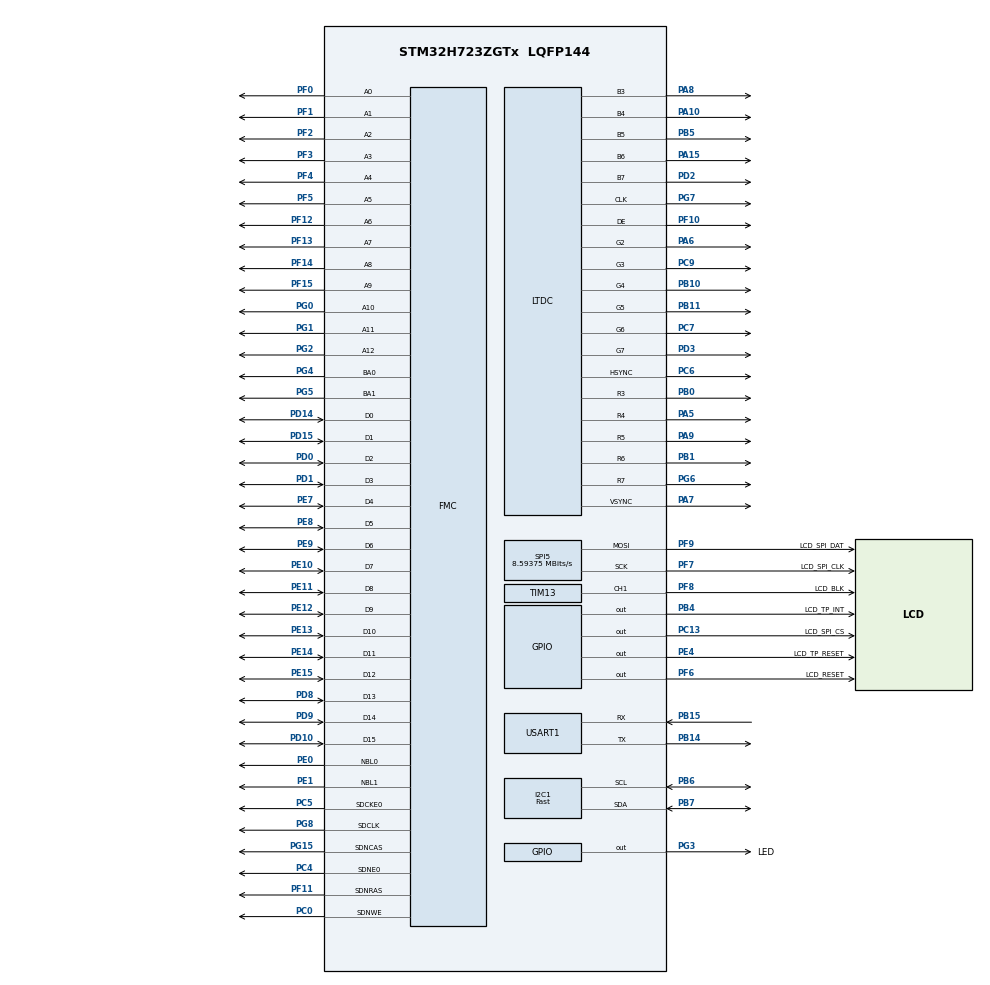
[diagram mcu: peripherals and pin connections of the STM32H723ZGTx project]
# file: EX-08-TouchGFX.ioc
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FMC.CASLatency1=FMC_SDRAM_CAS_LATENCY_2
FMC.ColumnBitsNumber1=FMC_SDRAM_COLUMN_BITS_NUM_9
FMC.ExitSelfRefreshDelay1=7
FMC.LoadToActiveDelay1=2
FMC.RCDDelay1=2
FMC.RPDelay1=2
FMC.ReadBurst1=FMC_SDRAM_RBURST_ENABLE
FMC.RowCycleDelay1=6
FMC.SDClockPeriod1=FMC_SDRAM_CLOCK_PERIOD_3
FMC.SelfRefreshTime1=4
FMC.WriteRecoveryTime1=2
I2C1.I2C_Speed_Mode=I2C_Fast
I2C1.Timing=0x00D049FB
LTDC.ActiveW=480
LTDC.Alpha_L0=255
LTDC.FBStartAdress_L0=0xC0000000
LTDC.HBP=50
LTDC.HFP=10
LTDC.ImageHeight_L0=480
LTDC.ImageWidth_L0=480
LTDC.Layers=0
LTDC.PixelFormat_L0=LTDC_PIXEL_FORMAT_RGB565
LTDC.VBP=20
LTDC.VFP=10
LTDC.VSync=8
LTDC.WindowX1_L0=480
LTDC.WindowY1_L0=480
Mcu.Family=STM32H7
Mcu.Name=STM32H723ZGTx
Mcu.Package=LQFP144
NVIC.LTDC_ER_IRQn=true\:5\:0\:true\:false\:true\:true\:true\:true
NVIC.LTDC_IRQn=true\:5\:0\:true\:false\:true\:true\:true\:true
NVIC.PriorityGroup=NVIC_PRIORITYGROUP_4
PA10.GPIO_Speed=GPIO_SPEED_FREQ_HIGH
PA10.Mode=RGB565
PA10.Signal=LTDC_B4
PA13(JTMS/SWDIO).Mode=Serial_Wire
PA13(JTMS/SWDIO).Signal=DEBUG_JTMS-SWDIO
PA14(JTCK/SWCLK).Mode=Serial_Wire
PA14(JTCK/SWCLK).Signal=DEBUG_JTCK-SWCLK
PA15(JTDI).GPIO_Speed=GPIO_SPEED_FREQ_HIGH
PA15(JTDI).Mode=RGB565
PA15(JTDI).Signal=LTDC_B6
PA5.GPIO_Speed=GPIO_SPEED_FREQ_HIGH
PA5.Mode=RGB565
PA5.Signal=LTDC_R4
PA6.GPIO_Speed=GPIO_SPEED_FREQ_HIGH
PA6.Mode=RGB565
PA6.Signal=LTDC_G2
PA7.GPIO_Speed=GPIO_SPEED_FREQ_HIGH
PA7.Mode=RGB565
PA7.Signal=LTDC_VSYNC
PA8.GPIO_Speed=GPIO_SPEED_FREQ_HIGH
PA8.Mode=RGB565
PA8.Signal=LTDC_B3
PA9.GPIO_Speed=GPIO_SPEED_FREQ_HIGH
PA9.Mode=RGB565
PA9.Signal=LTDC_R5
PB0.GPIO_Speed=GPIO_SPEED_FREQ_HIGH
PB0.Mode=RGB565
PB0.Signal=LTDC_R3
PB1.GPIO_Speed=GPIO_SPEED_FREQ_HIGH
PB1.Mode=RGB565
PB1.Signal=LTDC_R6
PB10.GPIO_Speed=GPIO_SPEED_FREQ_HIGH
PB10.Mode=RGB565
PB10.Signal=LTDC_G4
PB11.GPIO_Speed=GPIO_SPEED_FREQ_HIGH
PB11.Mode=RGB565
PB11.Signal=LTDC_G5
PB14.Mode=Asynchronous
PB14.Signal=USART1_TX
PB15.Mode=Asynchronous
PB15.Signal=USART1_RX
PB4(NJTRST).GPIO_Label=LCD_TP_INT
PB4(NJTRST).Signal=GPIO_Output
PB5.GPIO_Speed=GPIO_SPEED_FREQ_HIGH
PB5.Mode=RGB565
PB5.Signal=LTDC_B5
PB6.Mode=I2C
PB6.Signal=I2C1_SCL
PB7.Mode=I2C
PB7.Signal=I2C1_SDA
PC0.Signal=FMC_SDNWE
PC13.GPIO_Label=LCD_SPI_CS
PC13.PinState=GPIO_PIN_SET
PC13.Signal=GPIO_Output
PC4.Mode=SdramChipSelect1_1
PC4.Signal=FMC_SDNE0
PC5.Mode=SdramChipSelect1_1
PC5.Signal=FMC_SDCKE0
PC6.GPIO_Speed=GPIO_SPEED_FREQ_HIGH
PC6.Mode=RGB565
PC6.Signal=LTDC_HSYNC
PC7.GPIO_Speed=GPIO_SPEED_FREQ_HIGH
PC7.Mode=RGB565
PC7.Signal=LTDC_G6
PC9.GPIO_Speed=GPIO_SPEED_FREQ_HIGH
PC9.Mode=RGB565
PC9.Signal=LTDC_G3
PD0.Signal=FMC_D2_DA2
PD1.Signal=FMC_D3_DA3
PD10.Signal=FMC_D15_DA15
PD14.Signal=FMC_D0_DA0
PD15.Signal=FMC_D1_DA1
PD2.GPIO_Speed=GPIO_SPEED_FREQ_HIGH
PD2.Mode=RGB565
PD2.Signal=LTDC_B7
PD3.GPIO_Speed=GPIO_SPEED_FREQ_HIGH
PD3.Mode=RGB565
PD3.Signal=LTDC_G7
PD8.Signal=FMC_D13_DA13
PD9.Signal=FMC_D14_DA14
PE0.Signal=FMC_NBL0
PE1.Signal=FMC_NBL1
PE10.Signal=FMC_D7_DA7
PE11.Signal=FMC_D8_DA8
PE12.Signal=FMC_D9_DA9
PE13.Signal=FMC_D10_DA10
PE14.Signal=FMC_D11_DA11
PE15.Signal=FMC_D12_DA12
PE4.GPIO_Label=LCD_TP_RESET
PE4.Signal=GPIO_Output
PE7.Signal=FMC_D4_DA4
PE8.Signal=FMC_D5_DA5
PE9.Signal=FMC_D6_DA6
PF0.Signal=FMC_A0
PF1.Signal=FMC_A1
PF10.GPIO_Speed=GPIO_SPEED_FREQ_HIGH
PF10.Mode=RGB565
PF10.Signal=LTDC_DE
PF11.Signal=FMC_SDNRAS
PF12.Signal=FMC_A6
PF13.Signal=FMC_A7
PF14.Signal=FMC_A8
PF15.Signal=FMC_A9
PF2.Signal=FMC_A2
PF3.Signal=FMC_A3
PF4.Signal=FMC_A4
PF5.Signal=FMC_A5
PF6.GPIO_Label=LCD_RESET
PF6.PinState=GPIO_PIN_SET
PF6.Signal=GPIO_Output
PF7.GPIO_Label=LCD_SPI_CLK
PF7.GPIO_Speed=GPIO_SPEED_FREQ_HIGH
PF7.Mode=TX_Only_Simplex_Unidirect_Master
PF7.Signal=SPI5_SCK
PF8.GPIO_Label=LCD_BLK
PF8.Signal=S_TIM13_CH1
PF9.GPIO_Label=LCD_SPI_DAT
PF9.GPIO_Speed=GPIO_SPEED_FREQ_HIGH
PF9.Mode=TX_Only_Simplex_Unidirect_Master
PF9.Signal=SPI5_MOSI
PG0.Signal=FMC_A10
PG1.Signal=FMC_A11
PG15.Signal=FMC_SDNCAS
PG2.Signal=FMC_A12
PG3.GPIO_Label=LED
PG3.PinState=GPIO_PIN_SET
PG3.Signal=GPIO_Output
PG4.Signal=FMC_A14_BA0
PG5.Signal=FMC_A15_BA1
PG6.GPIO_Speed=GPIO_SPEED_FREQ_HIGH
PG6.Mode=RGB565
PG6.Signal=LTDC_R7
PG7.GPIO_Speed=GPIO_SPEED_FREQ_HIGH
PG7.Mode=RGB565
PG7.Signal=LTDC_CLK
PG8.Signal=FMC_SDCLK
PH0-OSC_IN.Mode=HSE-External-Oscillator
PH0-OSC_IN.Signal=RCC_OSC_IN
PH1-OSC_OUT.Mode=HSE-External-Oscillator
PH1-OSC_OUT.Signal=RCC_OSC_OUT
ProjectManager.HeapSize=0x200
ProjectManager.StackSize=0x400
ProjectManager.TargetToolchain=STM32CubeIDE
RCC.ADCFreq_Value=50390625
RCC.APB1Freq_Value=137500000
RCC.APB2Freq_Value=137500000
RCC.APB3Freq_Value=137500000
RCC.APB4Freq_Value=137500000
RCC.CortexFreq_Value=550000000
RCC.D1PPRE=RCC_APB3_DIV2
RCC.D2PPRE1=RCC_APB1_DIV2
RCC.D2PPRE2=RCC_APB2_DIV2
RCC.D3PPRE=RCC_APB4_DIV2
RCC.DIVM1=2
RCC.DIVN1=44
RCC.DIVP1=1
RCC.DIVR3=6
RCC.HCLKFreq_Value=275000000
RCC.HPRE=RCC_HCLK_DIV2
RCC.PLLFRACN=0
RCC.PLLSourceVirtual=RCC_PLLSOURCE_HSE
RCC.SYSCLKFreq_VALUE=550000000
RCC.SYSCLKSource=RCC_SYSCLKSOURCE_PLLCLK
RCC.USBFreq_Value=275000000
SH.FMC_A0.0=FMC_A0,13b-sda1
SH.FMC_A1.0=FMC_A1,13b-sda1
SH.FMC_A10.0=FMC_A10,13b-sda1
SH.FMC_A11.0=FMC_A11,13b-sda1
SH.FMC_A12.0=FMC_A12,13b-sda1
SH.FMC_A14_BA0.0=FMC_BA0,FourSdramBanks1
SH.FMC_A15_BA1.0=FMC_BA1,FourSdramBanks1
SH.FMC_A2.0=FMC_A2,13b-sda1
SH.FMC_A3.0=FMC_A3,13b-sda1
SH.FMC_A4.0=FMC_A4,13b-sda1
SH.FMC_A5.0=FMC_A5,13b-sda1
SH.FMC_A6.0=FMC_A6,13b-sda1
SH.FMC_A7.0=FMC_A7,13b-sda1
SH.FMC_A8.0=FMC_A8,13b-sda1
SH.FMC_A9.0=FMC_A9,13b-sda1
SH.FMC_D0_DA0.0=FMC_D0,sd-16b-d1
SH.FMC_D10_DA10.0=FMC_D10,sd-16b-d1
SH.FMC_D11_DA11.0=FMC_D11,sd-16b-d1
SH.FMC_D12_DA12.0=FMC_D12,sd-16b-d1
SH.FMC_D13_DA13.0=FMC_D13,sd-16b-d1
SH.FMC_D14_DA14.0=FMC_D14,sd-16b-d1
SH.FMC_D15_DA15.0=FMC_D15,sd-16b-d1
SH.FMC_D1_DA1.0=FMC_D1,sd-16b-d1
SH.FMC_D2_DA2.0=FMC_D2,sd-16b-d1
SH.FMC_D3_DA3.0=FMC_D3,sd-16b-d1
SH.FMC_D4_DA4.0=FMC_D4,sd-16b-d1
SH.FMC_D5_DA5.0=FMC_D5,sd-16b-d1
SH.FMC_D6_DA6.0=FMC_D6,sd-16b-d1
SH.FMC_D7_DA7.0=FMC_D7,sd-16b-d1
SH.FMC_D8_DA8.0=FMC_D8,sd-16b-d1
SH.FMC_D9_DA9.0=FMC_D9,sd-16b-d1
SH.FMC_NBL0.0=FMC_NBL0,Sd2ByteEnable1
SH.FMC_NBL1.0=FMC_NBL1,Sd2ByteEnable1
SH.FMC_SDCLK.0=FMC_SDCLK,13b-sda1
SH.FMC_SDNCAS.0=FMC_SDNCAS,13b-sda1
SH.FMC_SDNRAS.0=FMC_SDNRAS,13b-sda1
SH.FMC_SDNWE.0=FMC_SDNWE,13b-sda1
SH.S_TIM13_CH1.0=TIM13_CH1,PWM Generation1 CH1
SPI5.BaudRatePrescaler=SPI_BAUDRATEPRESCALER_16
SPI5.CalculateBaudRate=8.59375 MBits/s
SPI5.DataSize=SPI_DATASIZE_9BIT
SPI5.Direction=SPI_DIRECTION_2LINES_TXONLY
SPI5.Mode=SPI_MODE_MASTER
SPI5.VirtualType=VM_MASTER
STMicroelectronics.X-CUBE-TOUCHGFX.4.23.0.ApplicationCcGraphicsJjApplication=TouchGFXOoGenerator
STMicroelectronics.X-CUBE-TOUCHGFX.4.23.0.tgfx_address1=0xC0000000
STMicroelectronics.X-CUBE-TOUCHGFX.4.23.0.tgfx_address2=0xC0070800
STMicroelectronics.X-CUBE-TOUCHGFX.4.23.0.tgfx_buffering_strategy=Double
STMicroelectronics.X-CUBE-TOUCHGFX.4.23.0.tgfx_display_interface=disp_ltdc
STMicroelectronics.X-CUBE-TOUCHGFX.4.23.0.tgfx_hardware_accelerator=dma_2d
STMicroelectronics.X-CUBE-TOUCHGFX.4.23.0.tgfx_location=By Address
STMicroelectronics.X-CUBE-TOUCHGFX.4.23.0.tgfx_vsync=vsync_ltdc
STMicroelectronics.X-CUBE-TOUCHGFX.4.23.0_IsPackSelfContextualization=true
TIM13.Channel=TIM_CHANNEL_1
TIM13.Period=255
TIM13.Prescaler=53
USART1.VirtualMode-Asynchronous=VM_ASYNC
VP_CRC_VS_CRC.Mode=CRC_Activate
VP_DMA2D_VS_DMA2D.Mode=DMA2D_Activate
VP_STMicroelectronics.X-CUBE-TOUCHGFX_VS_GraphicsJjApplication_4.23.0.Mode=GraphicsJjApplication
VP_TIM13_VS_ClockSourceINT.Mode=Enable_Timer
board=custom

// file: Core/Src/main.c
/* USER CODE BEGIN Header */
/**
  ******************************************************************************
  * @file           : main.c
  * @brief          : Main program body
  ******************************************************************************
  * @attention
  *
  * Copyright (c) 2024 STMicroelectronics.
  * All rights reserved.
  *
  * This software is licensed under terms that can be found in the LICENSE file
  * in the root directory of this software component.
  * If no LICENSE file comes with this software, it is provided AS-IS.
  *
  ******************************************************************************
  */
/* USER CODE END Header */
#include "main.h"
#include "crc.h"
#include "dma2d.h"
#include "i2c.h"
#include "ltdc.h"
#include "spi.h"
#include "tim.h"
#include "usart.h"
#include "gpio.h"
#include "fmc.h"
#include "app_touchgfx.h"

/* USER CODE BEGIN Includes */

#include "sdram.h"
#include "st7701.h"
#include "gt911.h"

/* USER CODE END Includes */

void SystemClock_Config(void);

int main(void)
{

  /* MCU Configuration--------------------------------------------------------*/

  /* Reset of all peripherals, Initializes the Flash interface and the Systick. */
  HAL_Init();

  /* Configure the system clock */
  SystemClock_Config();

  /* Initialize all configured peripherals */
  MX_GPIO_Init();
  MX_USART1_UART_Init();
  MX_FMC_Init();
  MX_TIM13_Init();
  MX_SPI5_Init();
  MX_LTDC_Init();
  MX_I2C1_Init();
  MX_CRC_Init();
  MX_DMA2D_Init();
  MX_TouchGFX_Init();
  /* USER CODE BEGIN 2 */

  sdramInit();
  st7701Init();
  gt911Init();

  HAL_TIM_PWM_Start(&htim13, TIM_CHANNEL_1);
  htim13.Instance->CCR1 = 255;

  /* USER CODE END 2 */

  /* Infinite loop */
  while (1)
  {

  MX_TouchGFX_Process();
  }
}

void SystemClock_Config(void)
{
  RCC_OscInitTypeDef RCC_OscInitStruct = {0};
  RCC_ClkInitTypeDef RCC_ClkInitStruct = {0};

  /** Supply configuration update enable
  */
  HAL_PWREx_ConfigSupply(PWR_LDO_SUPPLY);

  /** Configure the main internal regulator output voltage
  */
  __HAL_PWR_VOLTAGESCALING_CONFIG(PWR_REGULATOR_VOLTAGE_SCALE0);

  while(!__HAL_PWR_GET_FLAG(PWR_FLAG_VOSRDY)) {}

  /** Initializes the RCC Oscillators according to the specified parameters
  * in the RCC_OscInitTypeDef structure.
  */
  RCC_OscInitStruct.OscillatorType = RCC_OSCILLATORTYPE_HSE;
  RCC_OscInitStruct.HSEState = RCC_HSE_ON;
  RCC_OscInitStruct.PLL.PLLState = RCC_PLL_ON;
  RCC_OscInitStruct.PLL.PLLSource = RCC_PLLSOURCE_HSE;
  RCC_OscInitStruct.PLL.PLLM = 2;
  RCC_OscInitStruct.PLL.PLLN = 44;
  RCC_OscInitStruct.PLL.PLLP = 1;
  RCC_OscInitStruct.PLL.PLLQ = 2;
  RCC_OscInitStruct.PLL.PLLR = 2;
  RCC_OscInitStruct.PLL.PLLRGE = RCC_PLL1VCIRANGE_3;
  RCC_OscInitStruct.PLL.PLLVCOSEL = RCC_PLL1VCOWIDE;
  RCC_OscInitStruct.PLL.PLLFRACN = 0;
  if (HAL_RCC_OscConfig(&RCC_OscInitStruct) != HAL_OK)
  {
    Error_Handler();
  }

  /** Initializes the CPU, AHB and APB buses clocks
  */
  RCC_ClkInitStruct.ClockType = RCC_CLOCKTYPE_HCLK|RCC_CLOCKTYPE_SYSCLK
                              |RCC_CLOCKTYPE_PCLK1|RCC_CLOCKTYPE_PCLK2
                              |RCC_CLOCKTYPE_D3PCLK1|RCC_CLOCKTYPE_D1PCLK1;
  RCC_ClkInitStruct.SYSCLKSource = RCC_SYSCLKSOURCE_PLLCLK;
  RCC_ClkInitStruct.SYSCLKDivider = RCC_SYSCLK_DIV1;
  RCC_ClkInitStruct.AHBCLKDivider = RCC_HCLK_DIV2;
  RCC_ClkInitStruct.APB3CLKDivider = RCC_APB3_DIV2;
  RCC_ClkInitStruct.APB1CLKDivider = RCC_APB1_DIV2;
  RCC_ClkInitStruct.APB2CLKDivider = RCC_APB2_DIV2;
  RCC_ClkInitStruct.APB4CLKDivider = RCC_APB4_DIV2;

  if (HAL_RCC_ClockConfig(&RCC_ClkInitStruct, FLASH_LATENCY_3) != HAL_OK)
  {
    Error_Handler();
  }
}

void Error_Handler(void)
{
  __disable_irq();
  while (1)
  {
  }
}
